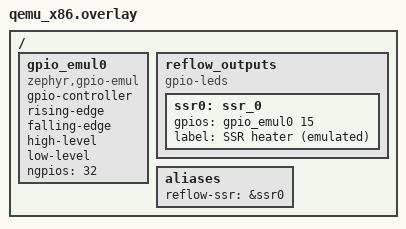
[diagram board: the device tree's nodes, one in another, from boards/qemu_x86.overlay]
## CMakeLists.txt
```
# SPDX-License-Identifier: Apache-2.0

cmake_minimum_required(VERSION 3.20.0)

# Same reason as tests/boot, tests/controller and tests/coldstart: reuse the
# application Kconfig so the test runs against the port, the client limit and
# the budgets the firmware ships with, instead of a restatement that can drift.
set(KCONFIG_ROOT ${CMAKE_CURRENT_SOURCE_DIR}/../../Kconfig)

find_package(Zephyr REQUIRED HINTS $ENV{ZEPHYR_BASE})
project(reflow_httpidle_tests LANGUAGES C)

set(SRC  ${CMAKE_CURRENT_SOURCE_DIR}/../../src)
set(CORE ${SRC}/core)
set(FAKE ${CMAKE_CURRENT_SOURCE_DIR}/../controller/src)

# httpd.c exactly as it is flashed, with two substitutions at link time:
#
#   - net_wait_fake.c takes the place of ${SRC}/net/l4.c. l4.c is the file that
#     talks to the network stack's event callbacks, and on a simulated platform
#     no link ever comes up, so every wait would be a real timeout.
#   - temp_fake.c takes the place of ${CORE}/temp.c, shared with tests/controller
#     rather than copied. httpd.c needs the telemetry channel and
#     reflow_cmd_post(), which live in controller.c, and controller.c needs a
#     thermocouple that a simulated SPI bus does not have.
#
# The link module (wifi.c / usb_net.c) is NOT in the image: the wait under test
# is link-agnostic by design, which is the property l4.c exists to provide.
target_sources(app PRIVATE
  src/main.c
  ${CMAKE_CURRENT_SOURCE_DIR}/../httpwait/src/net_wait_fake.c
  ${FAKE}/temp_fake.c
  ${SRC}/net/httpd.c
  ${SRC}/net/cmdparse.c
  ${SRC}/net/httpgate.c
  ${SRC}/net/profiles_json.c
  ${SRC}/net/sendbudget.c
  ${SRC}/telemetry_json.c
  ${CORE}/controller.c
  ${CORE}/heater.c
  ${CORE}/pid.c
  ${CORE}/profile.c
  ${CORE}/tempguard.c
)

#
# Zero failures: the link is up the first time the httpd thread asks for it.
# This suite is about the connection pool, and a server still waiting for the
# network would be one more thing happening while the scenarios run.
# tests/httpwait is where the wait itself is measured, with a non-zero value
# here. It has to be a build-time value either way, because the thread waits
# from K_THREAD_DEFINE before any test body could set anything (the lesson of
# RFO-G17, recorded in tests/coldstart).
target_compile_definitions(app PRIVATE REFLOW_NET_WAIT_FAKE_FAILURES=0)

# Same generated page as the firmware, from the same rule (RFO-B25): this
# image links httpd.c, so it needs index_html.h too, and a second copy of
# the recipe here is a second thing to drift.
include(${CMAKE_CURRENT_SOURCE_DIR}/../../cmake/index_html.cmake)
reflow_generate_index_html(${CMAKE_CURRENT_SOURCE_DIR}/../..)

target_include_directories(app PRIVATE ${SRC} ${CORE} ${SRC}/net ${FAKE}
                                       ${CMAKE_CURRENT_SOURCE_DIR}/src
                                       ${CMAKE_CURRENT_SOURCE_DIR}/../httpwait/src)
```

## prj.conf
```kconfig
CONFIG_ZTEST=y
CONFIG_ZBUS=y
CONFIG_GPIO=y
CONFIG_GPIO_EMUL=y

# The web UI is the subject here, so REFLOW_NET is on and brings its own
# networking dependencies through the application Kconfig. The display and the
# encoder are not in the image, for the reason tests/controller records.
CONFIG_REFLOW_NET=y
CONFIG_REFLOW_SHELL=n
CONFIG_REFLOW_UI_DISPLAY=n
CONFIG_REFLOW_UI_INPUT=n

# There is no radio and no USB host on a simulated platform: the only interface
# is the software loopback, which is enough to connect to the server the way a
# browser would. No link module is in the image either (see CMakeLists), so the
# Wi-Fi side of the Kconfig choice is inert here.
CONFIG_NET_LOOPBACK=y
CONFIG_NET_SOCKETS=y
CONFIG_NET_DHCPV4=n

# A remote command needs a token or the endpoint answers 503 (RFO-B02). This
# suite only reads telemetry, but leaving the token empty would make the one
# 503 answer indistinguishable from a route that is not there.
CONFIG_REFLOW_NET_TOKEN="testtoken"

# Loopback only, and no host-side networking backend. Left at their defaults,
# NETWORKING on these platforms brings up a SLIP/TAP link to the host: qemu is
# started with `-serial unix:/tmp/slip.sock`, which on this machine means the
# image produces no output at all, and native_sim wants a tap device the CI
# runner does not have. Upstream does the same thing for its loopback-only
# runs (samples/net/zperf/overlay-loopback-icount.conf).
# NET_LOOPBACK lives inside `if NET_DRIVERS` in drivers/net/Kconfig, so
# without this the symbol below is silently dropped and the image ends up
# with no interface at all: zsock_bind() on the wildcard address then fails
# with EADDRNOTAVAIL. It bit exactly one platform, because on qemu_x86
# something else already turns NET_DRIVERS on and on native_sim - with the
# tap driver off, below - nothing does.
CONFIG_NET_DRIVERS=y

CONFIG_NET_QEMU_SLIP=n
CONFIG_NET_SLIP_TAP=n
CONFIG_ETH_NATIVE_TAP=n

# The loopback driver delivers each packet synchronously in the sender's
# context, so the receive path runs nested on the caller's stack. Same reason
# and same order of magnitude as the upstream overlay above.
CONFIG_MAIN_STACK_SIZE=3072
CONFIG_ZTEST_STACK_SIZE=3072
CONFIG_NET_RX_STACK_SIZE=2560
CONFIG_NET_TX_STACK_SIZE=2560
CONFIG_NET_MGMT_EVENT_STACK_SIZE=2560

# RFO-G44. Room for BOTH ends of the loopback, and this is the one thing the
# scenario needed that the firmware dimensioning does not cover.
#
# In the field the clients live on other machines: the oven pays for the
# listener plus REFLOW_NET_MAX_CLIENTS accepted sockets, which is what the
# application Kconfig sizes and what httpd.c asserts. Here the test process
# hosts the server AND every client, so the same pool has to carry both sides -
# and with the shipped 10 the third silent connection failed with -ENOENT out of
# net_context_get().
#
# Raising it here does NOT relax what is under test. The defect is exhaustion of
# httpd.c's own clients[] array, sized by REFLOW_NET_MAX_CLIENTS, and that limit
# is untouched: the scenario still opens one more silent connection than the
# server has slots. What these two buy is only the right to be the client too.
CONFIG_NET_MAX_CONTEXTS=24
CONFIG_NET_MAX_CONN=24
```

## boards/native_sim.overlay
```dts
/*
 * SPDX-License-Identifier: Apache-2.0
 *
 * SIMULATION ONLY -- nothing here describes hardware.
 *
 * native_sim already provides a GPIO emulator as gpio0, so unlike the qemu_x86
 * overlay next to this one there is no controller to declare: only the SSR node
 * heater.c needs, and its alias. See that file for why the control core is in
 * an http server suite at all, and why there is no thermocouple node.
 *
 * native_sim does not run on Windows (PROCESSO.md section 10), which is why the
 * qemu_x86 overlay exists as well. Both platforms build the same source.
 */

#include <zephyr/dt-bindings/gpio/gpio.h>

/ {
	reflow_outputs {
		compatible = "gpio-leds";

		ssr0: ssr_0 {
			gpios = <&gpio0 15 GPIO_ACTIVE_HIGH>;
			label = "SSR heater (emulated)";
		};
	};

	aliases {
		reflow-ssr = &ssr0;
	};
};
```

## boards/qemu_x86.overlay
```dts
/*
 * SPDX-License-Identifier: Apache-2.0
 *
 * SIMULATION ONLY -- nothing here describes hardware.
 *
 * The subject of this suite is the http server, but the image links the
 * control core with it (httpd.c needs the telemetry channel and
 * reflow_cmd_post()), so heater.c needs its SSR node. There is deliberately no
 * thermocouple node: src/core/temp.c is not in this image,
 * tests/controller/src/temp_fake.c is.
 *
 * qemu_x86 has no GPIO controller of its own, so the emulator is declared here.
 * Pin 15 and GPIO_ACTIVE_HIGH mirror tests/boot and the application overlays.
 *
 * Nothing about the network is declared: the only interface in this image is
 * the software loopback, which is a Kconfig symbol and not a devicetree node.
 */

#include <zephyr/dt-bindings/gpio/gpio.h>

/ {
	gpio_emul0: gpio_emul0 {
		compatible = "zephyr,gpio-emul";
		gpio-controller;
		rising-edge;
		falling-edge;
		high-level;
		low-level;
		#gpio-cells = <2>;
		ngpios = <32>;
		status = "okay";
	};

	reflow_outputs {
		compatible = "gpio-leds";

		ssr0: ssr_0 {
			gpios = <&gpio_emul0 15 GPIO_ACTIVE_HIGH>;
			label = "SSR heater (emulated)";
		};
	};

	aliases {
		reflow-ssr = &ssr0;
	};
};
```

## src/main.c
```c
/*
 * SPDX-License-Identifier: Apache-2.0
 *
 * RFO-G44. The RFO-B08 scenario: connections that open and never speak.
 *
 * A client that connects and says nothing takes a slot. Four of them take
 * every slot, and from then on accept() closes each arrival on sight - the web
 * UI and the remote Stop button are gone until the board is reset. Nothing
 * malicious is needed: forgotten browser tabs are enough.
 *
 * Over the real loopback, not a fake, and the choice is the Gerente's with a
 * reason this suite inherits: this scenario depends on a COUNT OF CONNECTIONS,
 * which loopback gives for free and with full fidelity - opening N sockets and
 * never reading from them is the defect, literally. Its opposite is RFO-B07 in
 * tests/httpd/, which depends on when the peer stops reading - a decision of
 * the kernel's TCP window, and therefore one that needs a fake to be made on
 * command.
 *
 * So httpd.c here is linked, not included: nothing static is under test. What
 * is under test is what the server does with the sockets it is handed.
 */

#include <errno.h>
#include <string.h>

#include <zephyr/kernel.h>
#include <zephyr/net/socket.h>
#include <zephyr/ztest.h>

#include "net_wait_fake.h"

/*
 * From the symbol that sizes the pool, never a literal: if somebody changes
 * the dimensioning, this suite has to follow it instead of going on measuring
 * a number that stopped being the limit.
 */
#define POOL      CONFIG_REFLOW_NET_MAX_CLIENTS
#define IDLE_MS   CONFIG_REFLOW_NET_IDLE_BUDGET_MS

/* One more than the pool: the point is to exhaust it, not to fill it. */
#define IDLERS    (POOL + 1)

/* How long the suite waits for the server to come up before giving up. */
#define SETTLE_MS 4000

/*
 * Slack over the idle budget. The server only reclaims on its way round the
 * poll loop, so the wait has to cover the budget plus one pass - and on a
 * simulated platform under CI load, generously.
 *
 * Waited once, and then ONE request, rather than retrying in a loop. The first
 * version of this test polled every 250 ms and cost 1840 s on qemu_x86 - five
 * times the next slowest suite in the tree - because every probe opens a
 * connection against a listen backlog the silent clients have already filled,
 * and those connects do not fail quickly. There is nothing to poll for anyway:
 * the deadline is deterministic, so waiting it out once is both cheaper and a
 * sharper claim.
 */
#define RECLAIM_MS (IDLE_MS + 4000)

static int idlers[IDLERS];

static int connect_only(void)
{
	struct sockaddr_in addr = {
		.sin_family = AF_INET,
		.sin_port = htons(CONFIG_REFLOW_NET_HTTP_PORT),
	};
	int fd, ret;

	if (zsock_inet_pton(AF_INET, "127.0.0.1", &addr.sin_addr) != 1) {
		return -EINVAL;
	}

	fd = zsock_socket(AF_INET, SOCK_STREAM, IPPROTO_TCP);
	if (fd < 0) {
		return -errno;
	}
	if (zsock_connect(fd, (struct sockaddr *)&addr, sizeof(addr)) < 0) {
		ret = -errno;
		zsock_close(fd);
		return ret;
	}

	/* Deliberately nothing else: no request, no recv. This is the defect. */
	return fd;
}

/* A normal client: asks, reads, closes. Returns the bytes it got back. */
static int get_state(char *buf, size_t len)
{
	static const char req[] = "GET /api/state HTTP/1.1\r\n"
				  "Host: oven\r\n"
				  "Connection: close\r\n\r\n";
	struct sockaddr_in addr = {
		.sin_family = AF_INET,
		.sin_port = htons(CONFIG_REFLOW_NET_HTTP_PORT),
	};
	size_t got = 0;
	int fd, ret;

	if (zsock_inet_pton(AF_INET, "127.0.0.1", &addr.sin_addr) != 1) {
		return -EINVAL;
	}

	fd = zsock_socket(AF_INET, SOCK_STREAM, IPPROTO_TCP);
	if (fd < 0) {
		return -errno;
	}
	if (zsock_connect(fd, (struct sockaddr *)&addr, sizeof(addr)) < 0) {
		ret = -errno;
		zsock_close(fd);
		return ret;
	}
	if (zsock_send(fd, req, sizeof(req) - 1, 0) < 0) {
		ret = -errno;
		zsock_close(fd);
		return ret;
	}

	while (got + 1 < len) {
		ret = zsock_recv(fd, &buf[got], len - got - 1, 0);
		if (ret <= 0) {
			break;
		}
		got += (size_t)ret;
	}
	buf[got] = '\0';
	zsock_close(fd);

	return (int)got;
}

static bool wait_for(bool (*cond)(void), int32_t limit_ms)
{
	for (int32_t waited = 0; waited <= limit_ms; waited += 100) {
		if (cond()) {
			return true;
		}
		k_sleep(K_MSEC(100));
	}
	return cond();
}

static bool server_is_listening(void)
{
	char buf[256];

	return get_state(buf, sizeof(buf)) > 0;
}

static void *suite_setup(void)
{
	for (int i = 0; i < IDLERS; i++) {
		idlers[i] = -1;
	}
	return NULL;
}

static void scenario_teardown(void *f)
{
	ARG_UNUSED(f);

	for (int i = 0; i < IDLERS; i++) {
		if (idlers[i] >= 0) {
			zsock_close(idlers[i]);
			idlers[i] = -1;
		}
	}
}

/*
 * The acceptance criterion, and the assertion is about the client that comes
 * AFTER the silent ones - the operator arriving to press Stop. That is what
 * RFO-B08 broke, and asserting on the idle sockets themselves would measure
 * the wrong end of it.
 */
ZTEST(reflow_httpidle, test_silent_connections_do_not_lock_the_operator_out)
{
	char buf[512];
	int n;

	zassert_true(wait_for(server_is_listening, SETTLE_MS),
		     "fixture: the server never started listening on port %d",
		     CONFIG_REFLOW_NET_HTTP_PORT);

	/* More silent connections than the pool has slots. */
	for (int i = 0; i < IDLERS; i++) {
		idlers[i] = connect_only();
		zassert_true(idlers[i] >= 0,
			     "fixture: silent connection %d failed: %d",
			     i, idlers[i]);
	}

	/*
	 * Now the operator. Without the reclaim in httpd.c every slot is held
	 * by a socket that will never speak, so this accept() is closed on
	 * arrival and the request gets nothing back - for ever, because none of
	 * the holders is going anywhere.
	 *
	 * With it, the slots come back after IDLE_BUDGET_MS and the request is
	 * served. So the wait is not slack around a flaky test: it is the
	 * mechanism under test, and its length is the budget itself.
	 *
	 * One request after one wait, deliberately. Retrying would turn a
	 * deterministic deadline into "it worked eventually", and eventually is
	 * not what the operator gets.
	 */
	k_sleep(K_MSEC(RECLAIM_MS));
	n = get_state(buf, sizeof(buf));

	zassert_true(n > 0,
		     "a client arriving after %d silent connections got nothing "
		     "back %d ms later (pool is %d, idle budget %d ms). The "
		     "slots are held by sockets that never spoke, so the web UI "
		     "and the remote Stop button are gone until the board is "
		     "reset (RFO-B08)",
		     IDLERS, RECLAIM_MS, POOL, IDLE_MS);

	zassert_not_null(strstr(buf, "200 OK"),
			 "the answer was not a 200: %s", buf);
	zassert_not_null(strstr(buf, "temp_mc"),
			 "the answer carried no telemetry: %s", buf);
}

/*
 * The counterpart, and the reason the reclaim is written against silence
 * rather than against age: a connection that ASKS is served, and the pool is
 * not something the server empties on a timer.
 */
ZTEST(reflow_httpidle, test_a_client_that_speaks_is_served_immediately)
{
	char buf[512];
	int n;

	zassert_true(wait_for(server_is_listening, SETTLE_MS),
		     "fixture: the server never started listening");

	n = get_state(buf, sizeof(buf));

	zassert_true(n > 0, "a lone, well-behaved client got nothing back");
	zassert_not_null(strstr(buf, "200 OK"),
			 "the answer was not a 200: %s", buf);
}

ZTEST_SUITE(reflow_httpidle, NULL, suite_setup, NULL, scenario_teardown, NULL);
```
